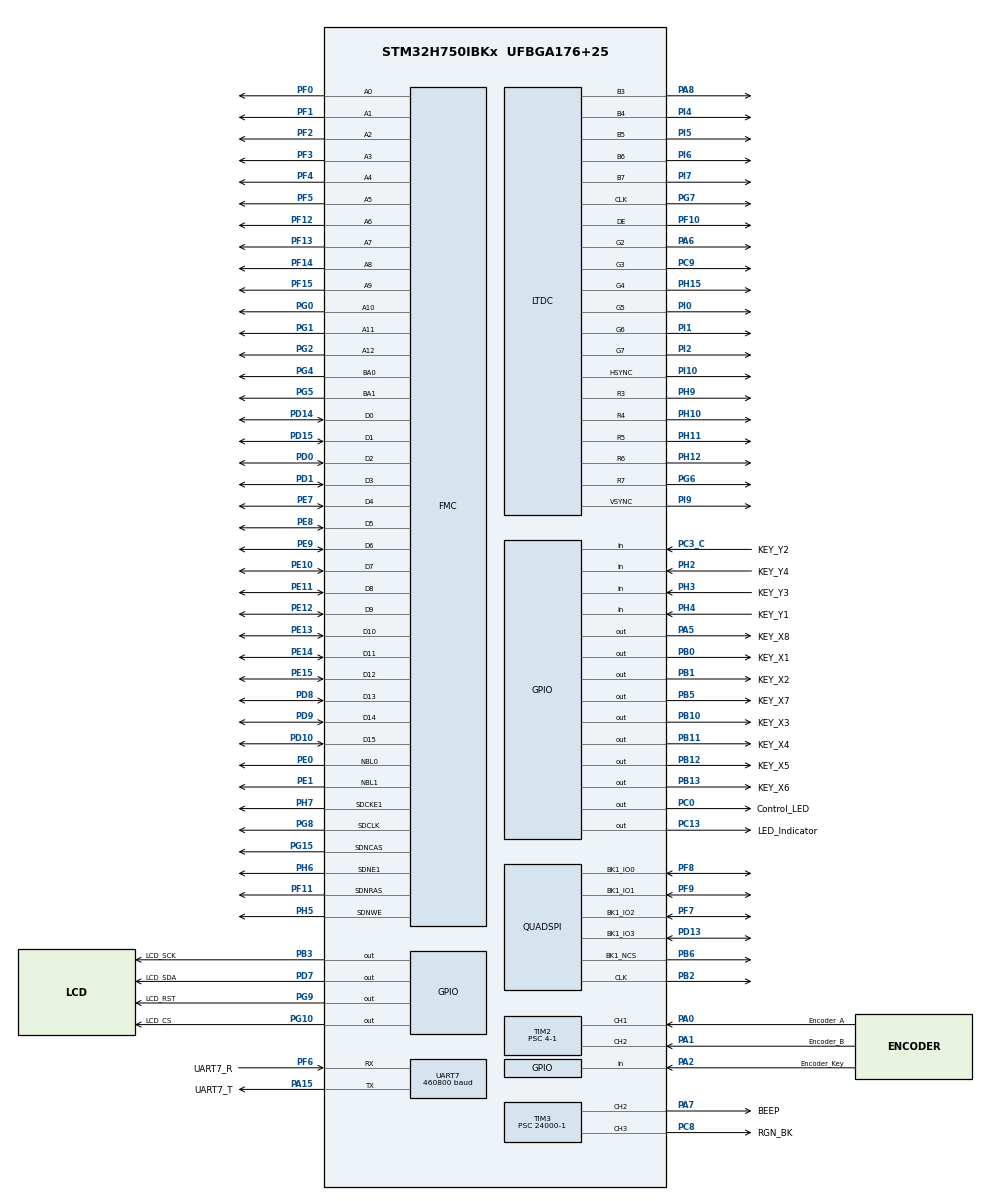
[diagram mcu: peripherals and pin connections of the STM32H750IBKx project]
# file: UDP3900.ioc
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CORTEX_M7.CPU_DCache=Enabled
CORTEX_M7.CPU_ICache=Enabled
CORTEX_M7.default_mode_Activation=1
DMA2D.ColorMode=DMA2D_OUTPUT_RGB565
Dma.Request0=UART7_RX
Dma.UART7_RX.0.Direction=DMA_PERIPH_TO_MEMORY
Dma.UART7_RX.0.EventEnable=DISABLE
Dma.UART7_RX.0.FIFOMode=DMA_FIFOMODE_DISABLE
Dma.UART7_RX.0.Instance=DMA1_Stream0
Dma.UART7_RX.0.MemDataAlignment=DMA_MDATAALIGN_BYTE
Dma.UART7_RX.0.MemInc=DMA_MINC_ENABLE
Dma.UART7_RX.0.Mode=DMA_NORMAL
Dma.UART7_RX.0.PeriphDataAlignment=DMA_PDATAALIGN_BYTE
Dma.UART7_RX.0.PeriphInc=DMA_PINC_DISABLE
Dma.UART7_RX.0.Polarity=HAL_DMAMUX_REQ_GEN_RISING
Dma.UART7_RX.0.Priority=DMA_PRIORITY_LOW
Dma.UART7_RX.0.RequestNumber=1
Dma.UART7_RX.0.SignalID=NONE
Dma.UART7_RX.0.SyncEnable=DISABLE
Dma.UART7_RX.0.SyncPolarity=HAL_DMAMUX_SYNC_NO_EVENT
Dma.UART7_RX.0.SyncRequestNumber=1
Dma.UART7_RX.0.SyncSignalID=NONE
FMC.CASLatency1=FMC_SDRAM_CAS_LATENCY_2
FMC.ColumnBitsNumber1=FMC_SDRAM_COLUMN_BITS_NUM_9
FMC.ExitSelfRefreshDelay1=8
FMC.LoadToActiveDelay1=2
FMC.RCDDelay1=2
FMC.RPDelay1=2
FMC.ReadBurst1=FMC_SDRAM_RBURST_ENABLE
FMC.ReadBurst2=FMC_SDRAM_RBURST_ENABLE
FMC.RowCycleDelay1=7
FMC.RowCycleDelay2=7
FMC.SDClockPeriod1=FMC_SDRAM_CLOCK_PERIOD_2
FMC.SelfRefreshTime1=7
FMC.WriteRecoveryTime1=5
FREERTOS.Tasks01=GUITask,24,1024,GUI_Task,As weak,NULL,Dynamic,NULL,NULL
FREERTOS.configCHECK_FOR_STACK_OVERFLOW=2
FREERTOS.configENABLE_FPU=1
FREERTOS.configGENERATE_RUN_TIME_STATS=1
FREERTOS.configTOTAL_HEAP_SIZE=0x20000
FREERTOS.configUSE_MALLOC_FAILED_HOOK=1
LTDC.ActiveH=960
LTDC.ActiveW=360
LTDC.Alpha0_L0=255
LTDC.FBStartAdress_L0=0xD0000000
LTDC.HBP=20
LTDC.HFP=20
LTDC.ImageHeight_L0=960
LTDC.ImageWidth_L0=240
LTDC.Layers=0
LTDC.PixelFormat_L0=LTDC_PIXEL_FORMAT_RGB565
LTDC.VFP=20
LTDC.VSync=8
LTDC.WindowX0_L0=120
LTDC.WindowX1_L0=359
LTDC.WindowY1_L0=959
Mcu.Family=STM32H7
Mcu.Name=STM32H750IBKx
Mcu.Package=UFBGA176+25
NVIC.DMA1_Stream0_IRQn=true\:5\:0\:true\:false\:true\:true\:false\:true\:true
NVIC.DMA2D_IRQn=true\:5\:0\:true\:false\:true\:true\:true\:true\:true
NVIC.PriorityGroup=NVIC_PRIORITYGROUP_4
NVIC.TIM6_DAC_IRQn=true\:15\:0\:false\:false\:true\:false\:false\:true\:true
NVIC.TimeBase=TIM6_DAC_IRQn
NVIC.TimeBaseIP=TIM6
NVIC.UART7_IRQn=true\:5\:0\:true\:false\:true\:true\:true\:true\:true
PA0.GPIO_Label=Encoder_A
PA0.Signal=S_TIM2_CH1_ETR
PA1.GPIO_Label=Encoder_B
PA1.Signal=S_TIM2_CH2
PA13\ (JTMS/SWDIO).Mode=Serial_Wire
PA13\ (JTMS/SWDIO).Signal=DEBUG_JTMS-SWDIO
PA14\ (JTCK/SWCLK).Mode=Serial_Wire
PA14\ (JTCK/SWCLK).Signal=DEBUG_JTCK-SWCLK
PA15\ (JTDI).GPIO_Label=UART7_T
PA15\ (JTDI).GPIO_PuPd=GPIO_PULLUP
PA15\ (JTDI).Mode=Asynchronous
PA15\ (JTDI).Signal=UART7_TX
PA2.GPIO_Label=Encoder_Key
PA2.GPIO_PuPd=GPIO_PULLDOWN
PA2.Signal=GPIO_Input
PA5.GPIO_Label=KEY_X8
PA5.GPIO_ModeDefaultOutputPP=GPIO_MODE_OUTPUT_PP
PA5.GPIO_PuPd=GPIO_NOPULL
PA5.GPIO_Speed=GPIO_SPEED_FREQ_LOW
PA5.PinState=GPIO_PIN_SET
PA5.Signal=GPIO_Output
PA6.GPIO_Speed=GPIO_SPEED_FREQ_VERY_HIGH
PA6.Mode=RGB565
PA6.Signal=LTDC_G2
PA7.GPIO_Label=BEEP
PA7.GPIO_PuPd=GPIO_PULLDOWN
PA7.Signal=S_TIM3_CH2
PA8.GPIO_Speed=GPIO_SPEED_FREQ_VERY_HIGH
PA8.Mode=RGB565
PA8.Signal=LTDC_B3
PB0.GPIO_Label=KEY_X1
PB0.GPIO_ModeDefaultOutputPP=GPIO_MODE_OUTPUT_PP
PB0.GPIO_PuPd=GPIO_NOPULL
PB0.GPIO_Speed=GPIO_SPEED_FREQ_LOW
PB0.PinState=GPIO_PIN_SET
PB0.Signal=GPIO_Output
PB1.GPIO_Label=KEY_X2
PB1.GPIO_ModeDefaultOutputPP=GPIO_MODE_OUTPUT_PP
PB1.GPIO_PuPd=GPIO_NOPULL
PB1.GPIO_Speed=GPIO_SPEED_FREQ_LOW
PB1.PinState=GPIO_PIN_SET
PB1.Signal=GPIO_Output
PB10.GPIO_Label=KEY_X3
PB10.GPIO_ModeDefaultOutputPP=GPIO_MODE_OUTPUT_PP
PB10.GPIO_PuPd=GPIO_NOPULL
PB10.GPIO_Speed=GPIO_SPEED_FREQ_LOW
PB10.PinState=GPIO_PIN_SET
PB10.Signal=GPIO_Output
PB11.GPIO_Label=KEY_X4
PB11.GPIO_ModeDefaultOutputPP=GPIO_MODE_OUTPUT_PP
PB11.GPIO_PuPd=GPIO_NOPULL
PB11.GPIO_Speed=GPIO_SPEED_FREQ_LOW
PB11.PinState=GPIO_PIN_SET
PB11.Signal=GPIO_Output
PB12.GPIO_Label=KEY_X5
PB12.GPIO_ModeDefaultOutputPP=GPIO_MODE_OUTPUT_PP
PB12.GPIO_PuPd=GPIO_NOPULL
PB12.GPIO_Speed=GPIO_SPEED_FREQ_LOW
PB12.PinState=GPIO_PIN_SET
PB12.Signal=GPIO_Output
PB13.GPIO_Label=KEY_X6
PB13.GPIO_ModeDefaultOutputPP=GPIO_MODE_OUTPUT_PP
PB13.GPIO_PuPd=GPIO_NOPULL
PB13.GPIO_Speed=GPIO_SPEED_FREQ_LOW
PB13.PinState=GPIO_PIN_SET
PB13.Signal=GPIO_Output
PB2.Mode=Single Bank 1
PB2.Signal=QUADSPI_CLK
PB3\ (JTDO/TRACESWO).GPIO_Label=LCD_SCK
PB3\ (JTDO/TRACESWO).GPIO_PuPd=GPIO_PULLUP
PB3\ (JTDO/TRACESWO).GPIO_Speed=GPIO_SPEED_FREQ_VERY_HIGH
PB3\ (JTDO/TRACESWO).PinState=GPIO_PIN_SET
PB3\ (JTDO/TRACESWO).Signal=GPIO_Output
PB5.GPIO_Label=KEY_X7
PB5.GPIO_ModeDefaultOutputPP=GPIO_MODE_OUTPUT_PP
PB5.GPIO_PuPd=GPIO_NOPULL
PB5.GPIO_Speed=GPIO_SPEED_FREQ_LOW
PB5.PinState=GPIO_PIN_SET
PB5.Signal=GPIO_Output
PB6.Mode=Single Bank 1
PB6.Signal=QUADSPI_BK1_NCS
PC0.GPIO_Label=Control_LED
PC0.GPIO_PuPd=GPIO_PULLDOWN
PC0.Signal=GPIO_Output
PC13.GPIO_Label=LED_Indicator
PC13.GPIO_PuPd=GPIO_PULLDOWN
PC13.Signal=GPIO_Output
PC14-OSC32_IN\ (OSC32_IN).Mode=LSE-External-Oscillator
PC14-OSC32_IN\ (OSC32_IN).Signal=RCC_OSC32_IN
PC15-OSC32_OUT\ (OSC32_OUT).Mode=LSE-External-Oscillator
PC15-OSC32_OUT\ (OSC32_OUT).Signal=RCC_OSC32_OUT
PC3_C.GPIO_Label=KEY_Y2
PC3_C.GPIO_Mode=GPIO_MODE_INPUT
PC3_C.GPIO_PuPd=GPIO_PULLUP
PC3_C.Signal=GPIO_Input
PC8.GPIO_Label=RGN_BK
PC8.Signal=S_TIM3_CH3
PC9.GPIO_Speed=GPIO_SPEED_FREQ_VERY_HIGH
PC9.Mode=RGB565
PC9.Signal=LTDC_G3
PD0.GPIO_PuPd=GPIO_PULLUP
PD0.Signal=FMC_D2_DA2
PD1.GPIO_PuPd=GPIO_PULLUP
PD1.Signal=FMC_D3_DA3
PD10.GPIO_PuPd=GPIO_PULLUP
PD10.Signal=FMC_D15_DA15
PD13.Mode=Single Bank 1
PD13.Signal=QUADSPI_BK1_IO3
PD14.GPIO_PuPd=GPIO_PULLUP
PD14.Signal=FMC_D0_DA0
PD15.GPIO_PuPd=GPIO_PULLUP
PD15.Signal=FMC_D1_DA1
PD7.GPIO_Label=LCD_SDA
PD7.GPIO_PuPd=GPIO_PULLUP
PD7.GPIO_Speed=GPIO_SPEED_FREQ_VERY_HIGH
PD7.PinState=GPIO_PIN_SET
PD7.Signal=GPIO_Output
PD8.GPIO_PuPd=GPIO_PULLUP
PD8.Signal=FMC_D13_DA13
PD9.GPIO_PuPd=GPIO_PULLUP
PD9.Signal=FMC_D14_DA14
PE0.GPIO_PuPd=GPIO_PULLUP
PE0.Signal=FMC_NBL0
PE1.GPIO_PuPd=GPIO_PULLUP
PE1.Signal=FMC_NBL1
PE10.GPIO_PuPd=GPIO_PULLUP
PE10.Signal=FMC_D7_DA7
PE11.GPIO_PuPd=GPIO_PULLUP
PE11.Signal=FMC_D8_DA8
PE12.GPIO_PuPd=GPIO_PULLUP
PE12.Signal=FMC_D9_DA9
PE13.GPIO_PuPd=GPIO_PULLUP
PE13.Signal=FMC_D10_DA10
PE14.GPIO_PuPd=GPIO_PULLUP
PE14.Signal=FMC_D11_DA11
PE15.GPIO_PuPd=GPIO_PULLUP
PE15.Signal=FMC_D12_DA12
PE7.GPIO_PuPd=GPIO_PULLUP
PE7.Signal=FMC_D4_DA4
PE8.GPIO_PuPd=GPIO_PULLUP
PE8.Signal=FMC_D5_DA5
PE9.GPIO_PuPd=GPIO_PULLUP
PE9.Signal=FMC_D6_DA6
PF0.GPIO_PuPd=GPIO_PULLUP
PF0.Signal=FMC_A0
PF1.GPIO_PuPd=GPIO_PULLUP
PF1.Signal=FMC_A1
PF10.GPIO_Speed=GPIO_SPEED_FREQ_VERY_HIGH
PF10.Mode=RGB565
PF10.Signal=LTDC_DE
PF11.GPIO_PuPd=GPIO_PULLUP
PF11.Signal=FMC_SDNRAS
PF12.GPIO_PuPd=GPIO_PULLUP
PF12.Signal=FMC_A6
PF13.GPIO_PuPd=GPIO_PULLUP
PF13.Signal=FMC_A7
PF14.GPIO_PuPd=GPIO_PULLUP
PF14.Signal=FMC_A8
PF15.GPIO_PuPd=GPIO_PULLUP
PF15.Signal=FMC_A9
PF2.GPIO_PuPd=GPIO_PULLUP
PF2.Signal=FMC_A2
PF3.GPIO_PuPd=GPIO_PULLUP
PF3.Signal=FMC_A3
PF4.GPIO_PuPd=GPIO_PULLUP
PF4.Signal=FMC_A4
PF5.GPIO_PuPd=GPIO_PULLUP
PF5.Signal=FMC_A5
PF6.GPIO_Label=UART7_R
PF6.Mode=Asynchronous
PF6.Signal=UART7_RX
PF7.Mode=Single Bank 1
PF7.Signal=QUADSPI_BK1_IO2
PF8.Mode=Single Bank 1
PF8.Signal=QUADSPI_BK1_IO0
PF9.Mode=Single Bank 1
PF9.Signal=QUADSPI_BK1_IO1
PG0.GPIO_PuPd=GPIO_PULLUP
PG0.Signal=FMC_A10
PG1.GPIO_PuPd=GPIO_PULLUP
PG1.Signal=FMC_A11
PG10.GPIO_Label=LCD_CS
PG10.GPIO_PuPd=GPIO_PULLUP
PG10.GPIO_Speed=GPIO_SPEED_FREQ_VERY_HIGH
PG10.PinState=GPIO_PIN_SET
PG10.Signal=GPIO_Output
PG15.GPIO_PuPd=GPIO_PULLUP
PG15.Signal=FMC_SDNCAS
PG2.GPIO_PuPd=GPIO_PULLUP
PG2.Signal=FMC_A12
PG4.GPIO_PuPd=GPIO_PULLUP
PG4.Signal=FMC_A14_BA0
PG5.GPIO_PuPd=GPIO_PULLUP
PG5.Signal=FMC_A15_BA1
PG6.GPIO_Speed=GPIO_SPEED_FREQ_VERY_HIGH
PG6.Mode=RGB565
PG6.Signal=LTDC_R7
PG7.GPIO_Speed=GPIO_SPEED_FREQ_VERY_HIGH
PG7.Mode=RGB565
PG7.Signal=LTDC_CLK
PG8.GPIO_PuPd=GPIO_NOPULL
PG8.Signal=FMC_SDCLK
PG9.GPIO_Label=LCD_RST
PG9.GPIO_PuPd=GPIO_PULLUP
PG9.GPIO_Speed=GPIO_SPEED_FREQ_VERY_HIGH
PG9.PinState=GPIO_PIN_SET
PG9.Signal=GPIO_Output
PH0-OSC_IN\ (PH0).Mode=HSE-External-Oscillator
PH0-OSC_IN\ (PH0).Signal=RCC_OSC_IN
PH1-OSC_OUT\ (PH1).Mode=HSE-External-Oscillator
PH1-OSC_OUT\ (PH1).Signal=RCC_OSC_OUT
PH10.GPIO_Speed=GPIO_SPEED_FREQ_VERY_HIGH
PH10.Mode=RGB565
PH10.Signal=LTDC_R4
PH11.GPIO_Speed=GPIO_SPEED_FREQ_VERY_HIGH
PH11.Mode=RGB565
PH11.Signal=LTDC_R5
PH12.GPIO_Speed=GPIO_SPEED_FREQ_VERY_HIGH
PH12.Mode=RGB565
PH12.Signal=LTDC_R6
PH15.GPIO_Speed=GPIO_SPEED_FREQ_VERY_HIGH
PH15.Mode=RGB565
PH15.Signal=LTDC_G4
PH2.GPIO_Label=KEY_Y4
PH2.GPIO_Mode=GPIO_MODE_INPUT
PH2.GPIO_PuPd=GPIO_PULLUP
PH2.Signal=GPIO_Input
PH3.GPIO_Label=KEY_Y3
PH3.GPIO_Mode=GPIO_MODE_INPUT
PH3.GPIO_PuPd=GPIO_PULLUP
PH3.Signal=GPIO_Input
PH4.GPIO_Label=KEY_Y1
PH4.GPIO_Mode=GPIO_MODE_INPUT
PH4.GPIO_PuPd=GPIO_PULLUP
PH4.Signal=GPIO_Input
PH5.GPIO_PuPd=GPIO_PULLUP
PH5.Signal=FMC_SDNWE
PH6.GPIO_PuPd=GPIO_PULLUP
PH6.Mode=SdramChipSelect2_1
PH6.Signal=FMC_SDNE1
PH7.GPIO_PuPd=GPIO_PULLUP
PH7.Mode=SdramChipSelect2_1
PH7.Signal=FMC_SDCKE1
PH9.GPIO_Speed=GPIO_SPEED_FREQ_VERY_HIGH
PH9.Mode=RGB565
PH9.Signal=LTDC_R3
PI0.GPIO_Speed=GPIO_SPEED_FREQ_VERY_HIGH
PI0.Mode=RGB565
PI0.Signal=LTDC_G5
PI1.GPIO_Speed=GPIO_SPEED_FREQ_VERY_HIGH
PI1.Mode=RGB565
PI1.Signal=LTDC_G6
PI10.GPIO_Speed=GPIO_SPEED_FREQ_VERY_HIGH
PI10.Mode=RGB565
PI10.Signal=LTDC_HSYNC
PI2.GPIO_Speed=GPIO_SPEED_FREQ_VERY_HIGH
PI2.Mode=RGB565
PI2.Signal=LTDC_G7
PI4.GPIO_Speed=GPIO_SPEED_FREQ_VERY_HIGH
PI4.Mode=RGB565
PI4.Signal=LTDC_B4
PI5.GPIO_Speed=GPIO_SPEED_FREQ_VERY_HIGH
PI5.Mode=RGB565
PI5.Signal=LTDC_B5
PI6.GPIO_Speed=GPIO_SPEED_FREQ_VERY_HIGH
PI6.Mode=RGB565
PI6.Signal=LTDC_B6
PI7.GPIO_Speed=GPIO_SPEED_FREQ_VERY_HIGH
PI7.Mode=RGB565
PI7.Signal=LTDC_B7
PI9.GPIO_Speed=GPIO_SPEED_FREQ_VERY_HIGH
PI9.Mode=RGB565
PI9.Signal=LTDC_VSYNC
ProjectManager.HeapSize=0x200
ProjectManager.StackSize=0x400
ProjectManager.TargetToolchain=MDK-ARM V5.32
QUADSPI.ChipSelectHighTime=QSPI_CS_HIGH_TIME_2_CYCLE
QUADSPI.ClockPrescaler=1
QUADSPI.FifoThreshold=32
QUADSPI.FlashSize=23
QUADSPI.SampleShifting=QSPI_SAMPLE_SHIFTING_HALFCYCLE
RCC.ADCFreq_Value=50390625
RCC.APB1Freq_Value=120000000
RCC.APB2Freq_Value=120000000
RCC.APB3Freq_Value=120000000
RCC.APB4Freq_Value=120000000
RCC.CortexFreq_Value=480000000
RCC.D1PPRE=RCC_APB3_DIV2
RCC.D2PPRE1=RCC_APB1_DIV2
RCC.D2PPRE2=RCC_APB2_DIV2
RCC.D3PPRE=RCC_APB4_DIV2
RCC.DIVM1=5
RCC.DIVM3=1
RCC.DIVN1=192
RCC.DIVN3=6
RCC.DIVR3=6
RCC.HCLKFreq_Value=240000000
RCC.HPRE=RCC_HCLK_DIV2
RCC.PLL2FRACN=0
RCC.PLL3FRACN=0
RCC.PLLFRACN=0
RCC.PLLSourceVirtual=RCC_PLLSOURCE_HSE
RCC.SYSCLKFreq_VALUE=480000000
RCC.SYSCLKSource=RCC_SYSCLKSOURCE_PLLCLK
RCC.USBFreq_Value=480000000
SH.FMC_A0.0=FMC_A0,13b-sda1
SH.FMC_A1.0=FMC_A1,13b-sda1
SH.FMC_A10.0=FMC_A10,13b-sda1
SH.FMC_A11.0=FMC_A11,13b-sda1
SH.FMC_A12.0=FMC_A12,13b-sda1
SH.FMC_A14_BA0.0=FMC_BA0,FourSdramBanks1
SH.FMC_A15_BA1.0=FMC_BA1,FourSdramBanks1
SH.FMC_A2.0=FMC_A2,13b-sda1
SH.FMC_A3.0=FMC_A3,13b-sda1
SH.FMC_A4.0=FMC_A4,13b-sda1
SH.FMC_A5.0=FMC_A5,13b-sda1
SH.FMC_A6.0=FMC_A6,13b-sda1
SH.FMC_A7.0=FMC_A7,13b-sda1
SH.FMC_A8.0=FMC_A8,13b-sda1
SH.FMC_A9.0=FMC_A9,13b-sda1
SH.FMC_D0_DA0.0=FMC_D0,sd-16b-d1
SH.FMC_D10_DA10.0=FMC_D10,sd-16b-d1
SH.FMC_D11_DA11.0=FMC_D11,sd-16b-d1
SH.FMC_D12_DA12.0=FMC_D12,sd-16b-d1
SH.FMC_D13_DA13.0=FMC_D13,sd-16b-d1
SH.FMC_D14_DA14.0=FMC_D14,sd-16b-d1
SH.FMC_D15_DA15.0=FMC_D15,sd-16b-d1
SH.FMC_D1_DA1.0=FMC_D1,sd-16b-d1
SH.FMC_D2_DA2.0=FMC_D2,sd-16b-d1
SH.FMC_D3_DA3.0=FMC_D3,sd-16b-d1
SH.FMC_D4_DA4.0=FMC_D4,sd-16b-d1
SH.FMC_D5_DA5.0=FMC_D5,sd-16b-d1
SH.FMC_D6_DA6.0=FMC_D6,sd-16b-d1
SH.FMC_D7_DA7.0=FMC_D7,sd-16b-d1
SH.FMC_D8_DA8.0=FMC_D8,sd-16b-d1
SH.FMC_D9_DA9.0=FMC_D9,sd-16b-d1
SH.FMC_NBL0.0=FMC_NBL0,Sd2ByteEnable1
SH.FMC_NBL1.0=FMC_NBL1,Sd2ByteEnable1
SH.FMC_SDCLK.0=FMC_SDCLK,13b-sda1
SH.FMC_SDNCAS.0=FMC_SDNCAS,13b-sda1
SH.FMC_SDNRAS.0=FMC_SDNRAS,13b-sda1
SH.FMC_SDNWE.0=FMC_SDNWE,13b-sda1
SH.S_TIM2_CH1_ETR.0=TIM2_CH1,Encoder_Interface
SH.S_TIM2_CH2.0=TIM2_CH2,Encoder_Interface
SH.S_TIM3_CH2.0=TIM3_CH2,PWM Generation2 CH2
SH.S_TIM3_CH3.0=TIM3_CH3,PWM Generation3 CH3
TIM2.EncoderMode=TIM_ENCODERMODE_TI12
TIM2.IC1Filter=0xf
TIM2.IC2Polarity=TIM_ICPOLARITY_FALLING
TIM2.Prescaler=4-1
TIM3.AutoReloadPreload=TIM_AUTORELOAD_PRELOAD_ENABLE
TIM3.Channel-PWM\ Generation2\ CH2=TIM_CHANNEL_2
TIM3.Channel-PWM\ Generation3\ CH3=TIM_CHANNEL_3
TIM3.Period=200-1
TIM3.Prescaler=24000-1
UART7.BaudRate=460800
VP_DMA2D_VS_DMA2D.Mode=DMA2D_Activate
VP_FREERTOS_VS_CMSIS_V2.Mode=CMSIS_V2
VP_MEMORYMAP_VS_MEMORYMAP.Mode=CurAppReg
VP_SYS_VS_tim6.Mode=TIM6
board=custom

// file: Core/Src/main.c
/* USER CODE BEGIN Header */
/**
  ******************************************************************************
  * @file           : main.c
  * @brief          : Main program body
  ******************************************************************************
  * @attention
  *
  * Copyright (c) 2026 STMicroelectronics.
  * All rights reserved.
  *
  * This software is licensed under terms that can be found in the LICENSE file
  * in the root directory of this software component.
  * If no LICENSE file comes with this software, it is provided AS-IS.
  *
  ******************************************************************************
  */
/* USER CODE END Header */
#include "main.h"
#include "FreeRTOS.h"
#include "cmsis_os2.h"
#include "dma.h"
#include "dma2d.h"
#include "ltdc.h"
#include "quadspi.h"
#include "tim.h"
#include "usart.h"
#include "gpio.h"
#include "fmc.h"

/* USER CODE BEGIN Includes */
typedef struct {
    uint32_t size;
    uint32_t sum;
    char fileName[128];
} FirmwareInfo_Def;

const FirmwareInfo_Def *firmwareInfo = 0;
/* USER CODE END Includes */

void SystemClock_Config(void);
static void MPU_Config(void);
void MX_FREERTOS_Init(void);

int main(void)
{

  /* USER CODE BEGIN 1 */
   __disable_irq();
   SCB->VTOR = 0x90002000;
    SCB_DisableDCache();
    SCB_DisableICache();
    SCB_InvalidateICache();
    SCB_InvalidateDCache();
    __enable_irq();
    firmwareInfo = (FirmwareInfo_Def *)(0x90000000 + 0x400000ul);

  /* USER CODE END 1 */

  /* MPU Configuration--------------------------------------------------------*/
  MPU_Config();

  /* Enable the CPU Cache */

  /* Enable I-Cache---------------------------------------------------------*/
  SCB_EnableICache();

  /* Enable D-Cache---------------------------------------------------------*/
  SCB_EnableDCache();

  /* MCU Configuration--------------------------------------------------------*/

  /* Reset of all peripherals, Initializes the Flash interface and the Systick. */
  HAL_Init();

  /* USER CODE BEGIN Init */
  mpu_memory_protection();

  /* USER CODE END Init */

  /* Configure the system clock */
  SystemClock_Config();

  /* Initialize all configured peripherals */
  MX_GPIO_Init();
  MX_DMA_Init();
  MX_UART7_Init();
  MX_DMA2D_Init();
  MX_LTDC_Init();
  MX_TIM3_Init();
  MX_FMC_Init();
  //MX_QUADSPI_Init();
  MX_TIM2_Init();
  /* USER CODE BEGIN 2 */
  led_init();

  /* USER CODE END 2 */

  /* Init scheduler */
  osKernelInitialize();  /* Call init function for freertos objects (in cmsis_os2.c) */
  MX_FREERTOS_Init();

  /* Start scheduler */
  osKernelStart();

  /* We should never get here as control is now taken by the scheduler */

  /* Infinite loop */
  while (1)
  {

  }
}

void SystemClock_Config(void)
{
  RCC_OscInitTypeDef RCC_OscInitStruct = {0};
  RCC_ClkInitTypeDef RCC_ClkInitStruct = {0};

  /** Supply configuration update enable
  */
  HAL_PWREx_ConfigSupply(PWR_LDO_SUPPLY);

  /** Configure the main internal regulator output voltage
  */
  __HAL_PWR_VOLTAGESCALING_CONFIG(PWR_REGULATOR_VOLTAGE_SCALE0);

  while(!__HAL_PWR_GET_FLAG(PWR_FLAG_VOSRDY)) {}

  /** Initializes the RCC Oscillators according to the specified parameters
  * in the RCC_OscInitTypeDef structure.
  */
  RCC_OscInitStruct.OscillatorType = RCC_OSCILLATORTYPE_HSE;
  RCC_OscInitStruct.HSEState = RCC_HSE_ON;
  RCC_OscInitStruct.PLL.PLLState = RCC_PLL_ON;
  RCC_OscInitStruct.PLL.PLLSource = RCC_PLLSOURCE_HSE;
  RCC_OscInitStruct.PLL.PLLM = 5;
  RCC_OscInitStruct.PLL.PLLN = 192;
  RCC_OscInitStruct.PLL.PLLP = 2;
  RCC_OscInitStruct.PLL.PLLQ = 2;
  RCC_OscInitStruct.PLL.PLLR = 2;
  RCC_OscInitStruct.PLL.PLLRGE = RCC_PLL1VCIRANGE_2;
  RCC_OscInitStruct.PLL.PLLVCOSEL = RCC_PLL1VCOWIDE;
  RCC_OscInitStruct.PLL.PLLFRACN = 0;
  if (HAL_RCC_OscConfig(&RCC_OscInitStruct) != HAL_OK)
  {
    Error_Handler();
  }

  /** Initializes the CPU, AHB and APB buses clocks
  */
  RCC_ClkInitStruct.ClockType = RCC_CLOCKTYPE_HCLK|RCC_CLOCKTYPE_SYSCLK
                              |RCC_CLOCKTYPE_PCLK1|RCC_CLOCKTYPE_PCLK2
                              |RCC_CLOCKTYPE_D3PCLK1|RCC_CLOCKTYPE_D1PCLK1;
  RCC_ClkInitStruct.SYSCLKSource = RCC_SYSCLKSOURCE_PLLCLK;
  RCC_ClkInitStruct.SYSCLKDivider = RCC_SYSCLK_DIV1;
  RCC_ClkInitStruct.AHBCLKDivider = RCC_HCLK_DIV2;
  RCC_ClkInitStruct.APB3CLKDivider = RCC_APB3_DIV2;
  RCC_ClkInitStruct.APB1CLKDivider = RCC_APB1_DIV2;
  RCC_ClkInitStruct.APB2CLKDivider = RCC_APB2_DIV2;
  RCC_ClkInitStruct.APB4CLKDivider = RCC_APB4_DIV2;

  if (HAL_RCC_ClockConfig(&RCC_ClkInitStruct, FLASH_LATENCY_4) != HAL_OK)
  {
    Error_Handler();
  }
}

 /* MPU Configuration */

void MPU_Config(void)
{
  MPU_Region_InitTypeDef MPU_InitStruct = {0};

  /* Disables the MPU */
  HAL_MPU_Disable();

  /** Initializes and configures the Region and the memory to be protected
  */
  MPU_InitStruct.Enable = MPU_REGION_ENABLE;
  MPU_InitStruct.Number = MPU_REGION_NUMBER0;
  MPU_InitStruct.BaseAddress = 0x0;
  MPU_InitStruct.Size = MPU_REGION_SIZE_4GB;
  MPU_InitStruct.SubRegionDisable = 0x87;
  MPU_InitStruct.TypeExtField = MPU_TEX_LEVEL0;
  MPU_InitStruct.AccessPermission = MPU_REGION_NO_ACCESS;
  MPU_InitStruct.DisableExec = MPU_INSTRUCTION_ACCESS_DISABLE;
  MPU_InitStruct.IsShareable = MPU_ACCESS_SHAREABLE;
  MPU_InitStruct.IsCacheable = MPU_ACCESS_NOT_CACHEABLE;
  MPU_InitStruct.IsBufferable = MPU_ACCESS_NOT_BUFFERABLE;

  HAL_MPU_ConfigRegion(&MPU_InitStruct);
  /* Enables the MPU */
  HAL_MPU_Enable(MPU_PRIVILEGED_DEFAULT);

}

void HAL_TIM_PeriodElapsedCallback(TIM_HandleTypeDef *htim)
{
  if (htim->Instance == TIM6)
  {
    HAL_IncTick();
  }
}

void Error_Handler(void)
{
  __disable_irq();
  while (1)
  {
  }
}

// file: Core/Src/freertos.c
/* USER CODE BEGIN Header */
/**
  ******************************************************************************
  * File Name          : freertos.c
  * Description        : Code for freertos applications
  ******************************************************************************
  * @attention
  *
  * Copyright (c) 2026 STMicroelectronics.
  * All rights reserved.
  *
  * This software is licensed under terms that can be found in the LICENSE file
  * in the root directory of this software component.
  * If no LICENSE file comes with this software, it is provided AS-IS.
  *
  ******************************************************************************
  */
/* USER CODE END Header */

#include "FreeRTOS.h"
#include "task.h"
#include "main.h"
#include "FreeRTOS.h"
#include "cmsis_os2.h"

/* Definitions for GUITask */
osThreadId_t GUITaskHandle;
const osThreadAttr_t GUITask_attributes = {
  .name = "GUITask",
  .stack_size = 1024 * 4,
  .priority = (osPriority_t) osPriorityNormal,
};

/* USER CODE BEGIN FunctionPrototypes */
osThreadId_t ledTaskHandle;
const osThreadAttr_t ledTask_attr = {
    .name = "LedTask",
    .stack_size = 256 * 4,
    .priority = osPriorityNormal,
};

/* 1. LED 显示任务 */
void StartLedTask(void *argument) {
    for(;;) {
    LED_TOGGLE();
    V_SET_LED(1);
    osDelay(500);
    V_SET_LED(0);
    osDelay(500);

    }
}

/* USER CODE END FunctionPrototypes */

void GUI_Task(void *argument);

void MX_FREERTOS_Init(void); /* (MISRA C 2004 rule 8.1) */

/* Hook prototypes */
void configureTimerForRunTimeStats(void);
unsigned long getRunTimeCounterValue(void);
void vApplicationStackOverflowHook(xTaskHandle xTask, char *pcTaskName);
void vApplicationMallocFailedHook(void);

/* USER CODE BEGIN 1 */
/* Functions needed when configGENERATE_RUN_TIME_STATS is on */
__weak void configureTimerForRunTimeStats(void)
{

}

__weak unsigned long getRunTimeCounterValue(void)
{
return 0;
}
/* USER CODE END 1 */

/* USER CODE BEGIN 4 */
void vApplicationStackOverflowHook(xTaskHandle xTask, char *pcTaskName)
{
   /* Run time stack overflow checking is performed if
   configCHECK_FOR_STACK_OVERFLOW is defined to 1 or 2. This hook function is
   called if a stack overflow is detected. */
}
/* USER CODE END 4 */

/* USER CODE BEGIN 5 */
void vApplicationMallocFailedHook(void)
{
   /* vApplicationMallocFailedHook() will only be called if
   configUSE_MALLOC_FAILED_HOOK is set to 1 in FreeRTOSConfig.h. It is a hook
   function that will get called if a call to pvPortMalloc() fails.
   pvPortMalloc() is called internally by the kernel whenever a task, queue,
   timer or semaphore is created. It is also called by various parts of the
   demo application. If heap_1.c or heap_2.c are used, then the size of the
   heap available to pvPortMalloc() is defined by configTOTAL_HEAP_SIZE in
   FreeRTOSConfig.h, and the xPortGetFreeHeapSize() API function can be used
   to query the size of free heap space that remains (although it does not
   provide information on how the remaining heap might be fragmented). */
}
/* USER CODE END 5 */

void MX_FREERTOS_Init(void) {

  /* Create the thread(s) */
  /* creation of GUITask */
  GUITaskHandle = osThreadNew(GUI_Task, NULL, &GUITask_attributes);

  /* USER CODE BEGIN RTOS_EVENTS */
  /* add events, ... */
  // ledTaskHandle      = osThreadNew(StartLedTask,      NULL, &ledTask_attr);
  /* USER CODE END RTOS_EVENTS */

}

/* USER CODE BEGIN Header_GUI_Task */

__weak void GUI_Task(void *argument)
{
  /* USER CODE BEGIN GUI_Task */

  for(;;)
  {
    osDelay(2);
  }
  /* USER CODE END GUI_Task */
}
